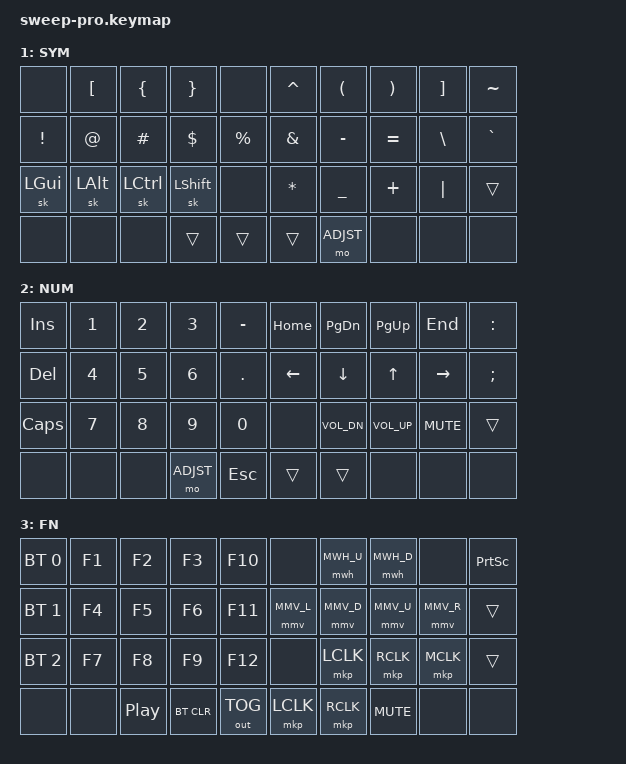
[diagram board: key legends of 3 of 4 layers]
/*
 * Copyright (c) 2020 The ZMK Contributors
 *
 * SPDX-License-Identifier: MIT
 */

#include <behaviors.dtsi>
#include <dt-bindings/zmk/mouse.h>
#include <dt-bindings/zmk/bt.h>
#include <dt-bindings/zmk/keys.h>
#include <dt-bindings/zmk/outputs.h>

#define DEFLT 0
#define LOWER 1
#define RAISE 2
#define ADJST 3

// mouse move settings

#define MMV_U MOVE_VERT(-650)
#define MMV_D MOVE_VERT(650)
#define MMV_L MOVE_HOR(-650)
#define MMV_R MOVE_HOR(650)

&mmv {
    time-to-max-speed-ms = <500>;
    acceleration-exponent = <1>;
};

// mouse wheel settings

#define MWH_U SCROLL_VERT(15)
#define MWH_D SCROLL_VERT(-15)
#define MWH_L SCROLL_HOR(-15)
#define MWH_R SCROLL_HOR(15)

&mwh {
    time-to-max-speed-ms = <2000>;
    acceleration-exponent = <0>;
};

&mt {
    flavor = "tap-preferred";
    tapping-term-ms = <200>;
    quick-tap-ms = <200>;
};

&lt {
    flavor = "hold-preferred";
    tapping-term-ms = <200>;
    quick-tap-ms = <200>;
};

/ {
    behaviors {
        mh: mod_hold_preferred {
            compatible = "zmk,behavior-hold-tap";
            label = "mod_hold_preferred";
            flavor = "hold-preferred";
            tapping-term-ms = <200>;
            quick-tap-ms = <200>;
            #binding-cells = <2>;
            bindings =
                <&kp>,
                <&kp>;
        };
        lh: layer_hold_preferred {
            compatible = "zmk,behavior-hold-tap";
            label = "layer_hold_preferred";
            flavor = "hold-preferred";
            tapping-term-ms = <200>;
            quick-tap-ms = <200>;
            #binding-cells = <2>;
            bindings =
                <&mo>,
                <&kp>;
        };
    };

    keymap {
        compatible = "zmk,keymap";

        default_layer {
            label = "ABC";
            bindings = <
        &kp Q        &kp W     &kp E          &kp R          &kp T      &kp Y           &kp U       &kp I      &kp O           &kp P
        &mt LSHFT A  &kp S     &kp D          &kp F          &kp G      &kp H           &kp J       &kp K      &kp L           &mt RSHFT APOS
        &mt LGUI Z   &kp X     &kp C          &kp V          &kp B      &kp N           &kp M       &kp COMMA  &kp DOT         &mt RALT SLASH
         &kp C_PP  &lh LOWER TAB  &mh LCTRL RET  &kp SPACE  &lh RAISE BSPC  &kp C_MUTE    
            >;

            sensor-bindings = <&inc_dec_kp RIGHT LEFT  &inc_dec_kp UP DOWN>;
        };

        lower_layer {
            label = "SYM";
            bindings = <
     &none  &kp LBKT   &kp LBRC  &kp RBRC       &none     &kp CARET   &kp LPAR   &kp RPAR  &kp RBKT  &kp TILDE
  &kp EXCL    &kp AT   &kp HASH  &kp DLLR   &kp PRCNT      &kp AMPS  &kp MINUS  &kp EQUAL  &kp BSLH  &kp GRAVE
  &sk LGUI  &sk LALT  &sk LCTRL  &sk LSHFT      &none     &kp ASTRK  &kp UNDER   &kp PLUS  &kp PIPE     &trans
     &none     &none      &none     &trans     &trans        &trans  &mo ADJST      &none     &none      &none
            >;

            sensor-bindings = <&inc_dec_kp TAB LS(TAB)  &inc_dec_kp PG_UP PG_DN>;
        };

        raise_layer {
            label = "NUM";
            bindings = <
   &kp INS  &kp N1  &kp N2     &kp N3  &kp MINUS  &kp HOME     &kp PG_DN     &kp PG_UP     &kp END  &kp COLON
   &kp DEL  &kp N4  &kp N5     &kp N6    &kp DOT  &kp LEFT      &kp DOWN        &kp UP   &kp RIGHT   &kp SEMI
  &kp CAPS  &kp N7  &kp N8     &kp N9     &kp N0     &none  &kp C_VOL_DN  &kp C_VOL_UP  &kp C_MUTE     &trans
     &none   &none   &none  &mo ADJST    &kp ESC    &trans        &trans         &none       &none      &none
            >;

            sensor-bindings = <&inc_dec_kp TAB LS(TAB)  &inc_dec_kp PG_UP PG_DN>;
        };

        adjust_layer {
            label = "FN";
            bindings = <
  &bt BT_SEL 0  &kp F1    &kp F2      &kp F3       &kp F10       &none  &mwh MWH_U  &mwh MWH_D       &none  &kp PSCRN
  &bt BT_SEL 1  &kp F4    &kp F5      &kp F6       &kp F11  &mmv MMV_L  &mmv MMV_D  &mmv MMV_U  &mmv MMV_R     &trans
  &bt BT_SEL 2  &kp F7    &kp F8      &kp F9       &kp F12       &none   &mkp LCLK   &mkp RCLK   &mkp MCLK     &trans
         &none   &none  &kp C_PP  &bt BT_CLR  &out OUT_TOG   &mkp LCLK   &mkp RCLK  &kp C_MUTE       &none      &none
            >;

            sensor-bindings = <&inc_dec_kp C_NEXT C_PREV  &inc_dec_kp C_VOL_DN C_VOL_UP>;
        };
    };
};
